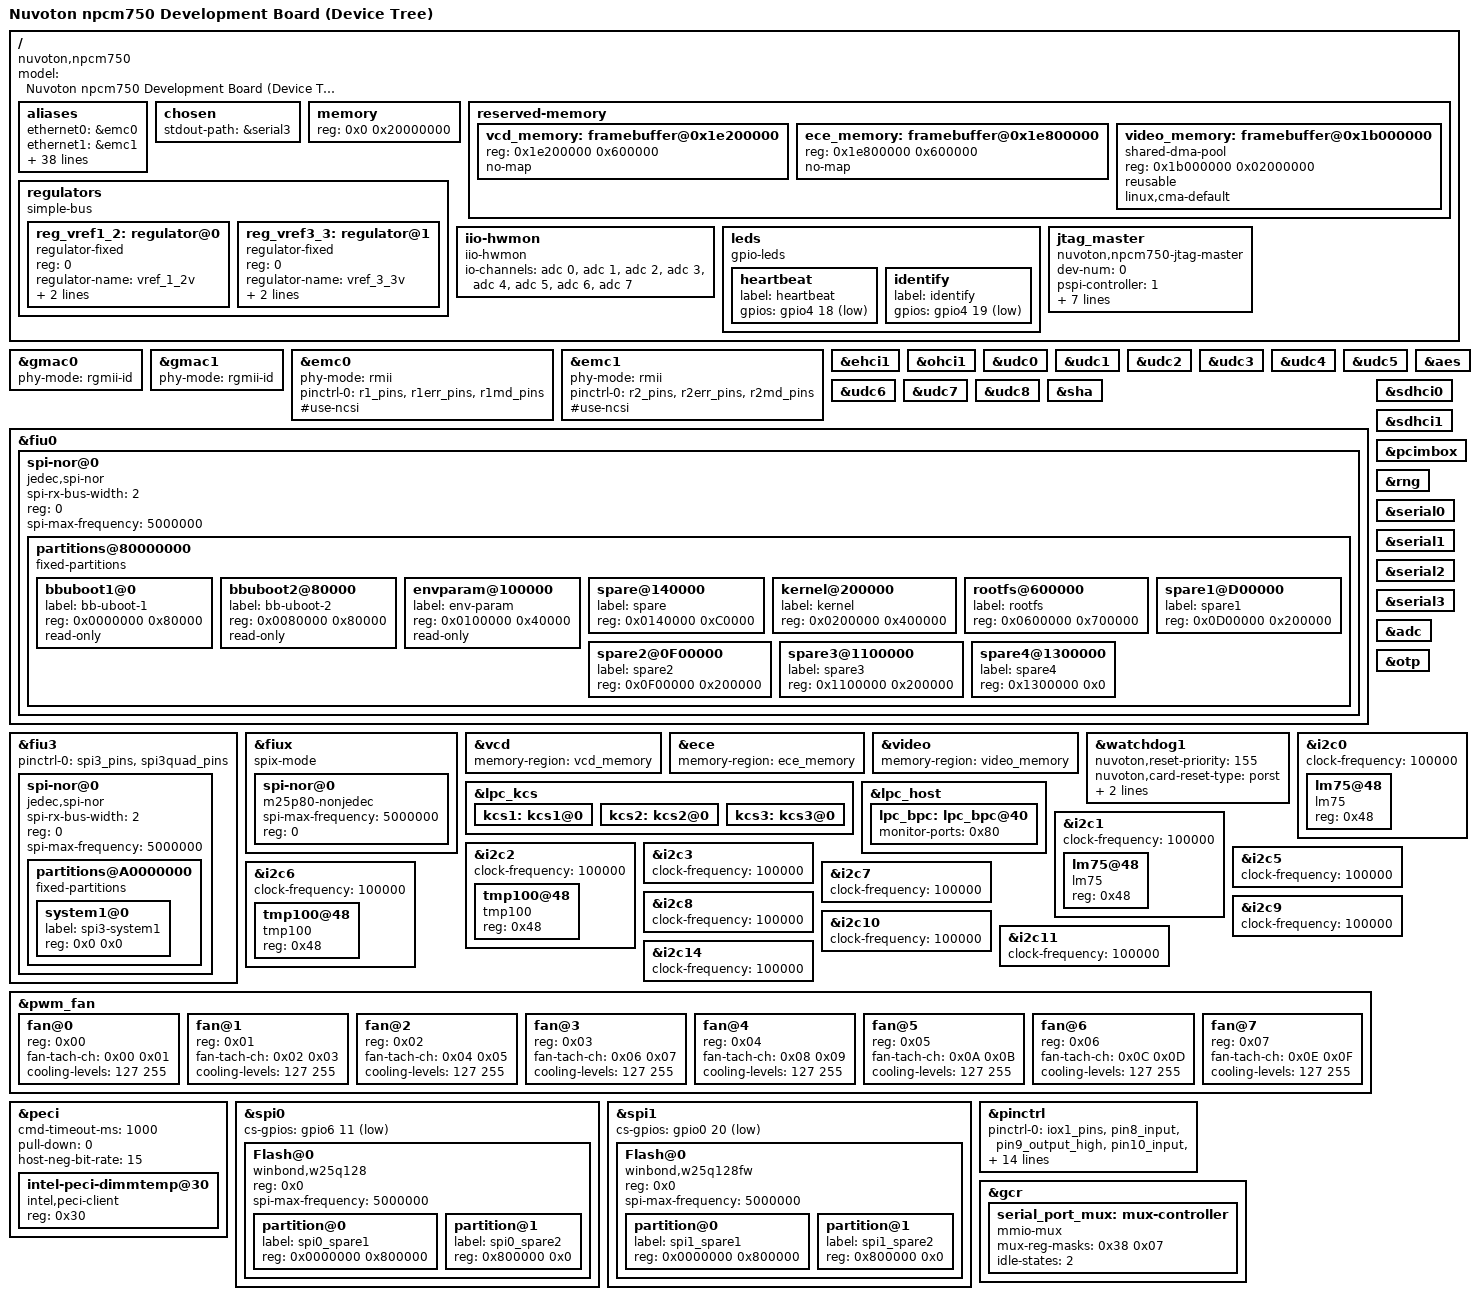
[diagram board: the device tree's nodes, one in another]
// SPDX-License-Identifier: GPL-2.0
// Copyright (c) 2018 Nuvoton Technology tomer.maimon@nuvoton.com
// Copyright 2018 Google, Inc.

/dts-v1/;
#include "nuvoton-npcm750.dtsi"
#include "dt-bindings/gpio/gpio.h"
#include "nuvoton-npcm750-pincfg-evb.dtsi"

/ {
	model = "Nuvoton npcm750 Development Board (Device Tree)";
	compatible = "nuvoton,npcm750";

	aliases {
		ethernet0 = &emc0;
		ethernet1 = &emc1;
		ethernet2 = &gmac0;
		ethernet3 = &gmac1;
		serial0 = &serial0;
		serial1 = &serial1;
		serial2 = &serial2;
		serial3 = &serial3;
		udc0 = &udc0;
		udc1 = &udc1;
		udc2 = &udc2;
		udc3 = &udc3;
		udc4 = &udc4;
		udc5 = &udc5;
		udc6 = &udc6;
		udc7 = &udc7;
		udc8 = &udc8;
		/* udc9 = &udc9; */
		emmc0 = &sdhci0;
		emmc1 = &sdhci1;
		i2c0 = &i2c0;
		i2c1 = &i2c1;
		i2c2 = &i2c2;
		i2c3 = &i2c3;
		i2c4 = &i2c4;
		i2c5 = &i2c5;
		i2c6 = &i2c6;
		i2c7 = &i2c7;
		i2c8 = &i2c8;
		i2c9 = &i2c9;
		i2c10 = &i2c10;
		i2c11 = &i2c11;
		i2c12 = &i2c12;
		i2c13 = &i2c13;
		i2c14 = &i2c14;
		i2c15 = &i2c15;
		spi0 = &spi0;
		spi1 = &spi1;
		fiu0 = &fiu0;
		fiu1 = &fiu3;
		fiu2 = &fiux;
	};

	chosen {
		stdout-path = &serial3;
	};

	memory {
		device_type = "memory";
		reg = <0x0 0x20000000>;
	};

	reserved-memory {
		#address-cells = <1>;
		#size-cells = <1>;
		ranges;

		vcd_memory: framebuffer@0x1e200000 {
			reg = <0x1e200000 0x600000>;
			no-map;
		};

		ece_memory: framebuffer@0x1e800000 {
			reg = <0x1e800000 0x600000>;
			no-map;
		};

		video_memory: framebuffer@0x1b000000 {
			compatible = "shared-dma-pool";
			reg = <0x1b000000 0x02000000>;
			reusable;
			linux,cma-default;
		};
	};

	regulators {
		compatible = "simple-bus";
		#address-cells = <1>;
		#size-cells = <0>;

		reg_vref1_2: regulator@0 {
			compatible = "regulator-fixed";
			reg = <0>;
			regulator-name = "vref_1_2v";
			regulator-min-microvolt = <1200000>;
			regulator-max-microvolt = <1200000>;
		};
		reg_vref3_3: regulator@1 {
			compatible = "regulator-fixed";
			reg = <0>;
			regulator-name = "vref_3_3v";
			regulator-min-microvolt = <3300000>;
			regulator-max-microvolt = <3300000>;
		};
	};

 	iio-hwmon {
		compatible = "iio-hwmon";
		io-channels = <&adc 0>, <&adc 1>, <&adc 2>, <&adc 3>,
			<&adc 4>, <&adc 5>, <&adc 6>, <&adc 7>;
	};

	leds {
		compatible = "gpio-leds";

		heartbeat {
			label = "heartbeat";
			gpios = <&gpio4 18 1>;
		};

		identify {
			label = "identify";
			gpios = <&gpio4 19 1>;
		};
	};

	jtag_master {
		compatible = "nuvoton,npcm750-jtag-master";
		#address-cells = <1>;
		#size-cells = <1>;

		dev-num = <0>;
		pspi-controller = <1>; /* pspi1 */
		reg = <0xf0200000 0x1000>;
		interrupts = <GIC_SPI 31 IRQ_TYPE_LEVEL_HIGH>;
		clocks = <&clk NPCM7XX_CLK_APB5>;

		jtag-gpios = <&gpio5 15 GPIO_ACTIVE_HIGH>, /* TCK */
				<&gpio5 16 GPIO_ACTIVE_HIGH>, /* TDI */
				<&gpio5 17 GPIO_ACTIVE_HIGH>, /* TDO */
				<&gpio6 11 GPIO_ACTIVE_HIGH>; /* TMS */
		jtag-gpios-reg = <0xf0015000 0xf0015000
						  0xf0015000 0xf0016000>;
		status = "okay";
	};
};

&gmac0 {
	phy-mode = "rgmii-id";
	status = "okay";
};

&gmac1 {
	phy-mode = "rgmii-id";
	status = "okay";
};

&emc0 {
	phy-mode = "rmii";
	pinctrl-0 = <&r1_pins
			&r1err_pins
			&r1md_pins>;
	#use-ncsi; /* add this to support ncsi */
	status = "okay";
};

&emc1 {
	phy-mode = "rmii";
	pinctrl-0 = <&r2_pins
			&r2err_pins
			&r2md_pins>;
	#use-ncsi; /* add this to support ncsi */
	status = "okay";
};

&ehci1 {
	status = "okay";
};

&ohci1 {
	status = "okay";
};

&udc0 {
	status = "okay";
};

&udc1 {
	status = "okay";
};

&udc2 {
	status = "okay";
};

&udc3 {
	status = "okay";
};

&udc4 {
	status = "okay";
};

&udc5 {
	status = "okay";
};

&udc6 {
	status = "okay";
};

&udc7 {
	status = "okay";
};

&udc8 {
	status = "okay";
};

/* using USB host instead of UDC9*/ 
/*&udc9 {
	status = "okay";
}; */

&aes {
	status = "okay";
};

&sha {
	status = "okay";
};

&fiu0 {
	status = "okay";
	spi-nor@0 {
		compatible = "jedec,spi-nor";
		#address-cells = <1>;
		#size-cells = <1>;
		spi-rx-bus-width = <2>;
		reg = <0>;
		spi-max-frequency = <5000000>;
		partitions@80000000 {
			compatible = "fixed-partitions";
			#address-cells = <1>;
			#size-cells = <1>;
			bbuboot1@0 {
				label = "bb-uboot-1";
				reg = <0x0000000 0x80000>;
				read-only;
				};
			bbuboot2@80000 {
				label = "bb-uboot-2";
				reg = <0x0080000 0x80000>;
				read-only;
				};
			envparam@100000 {
				label = "env-param";
				reg = <0x0100000 0x40000>;
				read-only;
				};
			spare@140000 {
				label = "spare";
				reg = <0x0140000 0xC0000>;
				};
			kernel@200000 {
				label = "kernel";
				reg = <0x0200000 0x400000>;
				};
			rootfs@600000 {
				label = "rootfs";
				reg = <0x0600000 0x700000>;
				};
			spare1@D00000 {
				label = "spare1";
				reg = <0x0D00000 0x200000>;
				};
			spare2@0F00000 {
				label = "spare2";
				reg = <0x0F00000 0x200000>;
				};
			spare3@1100000 {
				label = "spare3";
				reg = <0x1100000 0x200000>;
				};
			spare4@1300000 {
				label = "spare4";
				reg = <0x1300000 0x0>;
			};
		};
	};
};

&fiu3 {
	pinctrl-0 = <&spi3_pins>, <&spi3quad_pins>;
	status = "okay";
	spi-nor@0 {
		compatible = "jedec,spi-nor";
		#address-cells = <1>;
		#size-cells = <1>;
		spi-rx-bus-width = <2>;
		reg = <0>;
		spi-max-frequency = <5000000>;
		partitions@A0000000 {
			compatible = "fixed-partitions";
			#address-cells = <1>;
			#size-cells = <1>;
			system1@0 {
				label = "spi3-system1";
				reg = <0x0 0x0>;
			};
		};
	};
};

&fiux {
	status = "okay";
	spix-mode;
	spi-nor@0 {
		compatible = "m25p80-nonjedec";
		spi-max-frequency = <5000000>;
		#address-cells = <1>;
		#size-cells = <1>;
		reg = <0>;
	};
};

/* using GPIO29 for reset RC and EP signal */
/*&pci_rc {
	rst-rc-pci = <&gpio0 29 1>;
	rst-ep-pci = <&gpio0 29 1>;
	status = "okay";
};*/

&sdhci0 {
	status = "okay";
};

&sdhci1 {
	status = "okay";
};

&pcimbox {
	status = "okay";
};

&vcd {
	status = "okay";
	memory-region = <&vcd_memory>;
};

&ece {
	status = "okay";
	memory-region = <&ece_memory>;
};

&video {
	memory-region = <&video_memory>;
	status = "okay";
};

&watchdog1 {
	nuvoton,reset-priority = <155>;
	nuvoton,card-reset-type = "porst";
	nuvoton,ext1-reset-type = "wd1";
	nuvoton,ext2-reset-type = "sw2";
	status = "okay";
};

&rng {
	status = "okay";
};

&serial0 {
	status = "okay";
};

&serial1 {
	status = "okay";
};

&serial2 {
	status = "okay";
};

&serial3 {
	status = "okay";
};

&adc {
	/* enable external vref */
	/*vref-supply = <&reg_vref1_2>;*/
	#io-channel-cells = <1>;
	status = "okay";
};

&otp {
	status = "okay";
};

&lpc_kcs {
	kcs1: kcs1@0 {
		status = "okay";
	};

	kcs2: kcs2@0 {
		status = "okay";
	};

	kcs3: kcs3@0 {
		status = "okay";
	};
};

&lpc_host {
	lpc_bpc: lpc_bpc@40 {
		monitor-ports = <0x80>;
		status = "okay";
	};
};

/* I2C mux example */
/*i2cmux0 {
	compatible = "nuvoton,i2c-mux-npcm";
	#address-cells = <1>;
	#size-cells = <0>;

	status = "okay";
	i2c-parent = <&i2c1>;
	syscon = <&gcr>;
	nuvoton,i2c-number = <1>;

	pinctrl-names = "default";
	pinctrl-0 = <&smb1_pins &smb1b_pins &smb1c_pins &smb1d_pins>;
	i2c_segment_number = <0>, <1>, <2>, <3>;

	i2c@2 {
		reg = <2>;
		#address-cells = <1>;
		#size-cells = <0>;
		status = "okay";

		eeprom {
			compatible = "atmel,24c04";
			reg = <0x50>;
			status = "okay";
		};
	};
};*/

/* lm75 on SVB */
&i2c0 {
	clock-frequency = <100000>;
	status = "okay";
	lm75@48 {
		compatible = "lm75";
		reg = <0x48>;
		status = "okay";
	};
};

/* lm75 on EB */
&i2c1 {
	clock-frequency = <100000>;
	status = "okay";
	lm75@48 {
		compatible = "lm75";
		reg = <0x48>;
		status = "okay";
	};
};

/* tmp100 on EB */
&i2c2 {
	clock-frequency = <100000>;
	status = "okay";
	tmp100@48 {
		compatible = "tmp100";
		reg = <0x48>;
		status = "okay";
	};
};

&i2c3 {
	clock-frequency = <100000>;
	status = "okay";
};

&i2c5 {
	clock-frequency = <100000>;
	status = "okay";
};

/* tmp100 on SVB */
&i2c6 {
	clock-frequency = <100000>;
	status = "okay";
	tmp100@48 {
		compatible = "tmp100";
		reg = <0x48>;
		status = "okay";
	};
};

&i2c7 {
	clock-frequency = <100000>;
	status = "okay";
};

&i2c8 {
	clock-frequency = <100000>;
	status = "okay";
};

&i2c9 {
	clock-frequency = <100000>;
	status = "okay";
};

&i2c10 {
	clock-frequency = <100000>;
	status = "okay";
};

&i2c11 {
	clock-frequency = <100000>;
	status = "okay";
};

&i2c14 {
	clock-frequency = <100000>;
	status = "okay";
};

&pwm_fan {
	status = "okay";
	fan@0 {
		reg = <0x00>;
		fan-tach-ch = /bits/ 8 <0x00 0x01>;
		cooling-levels = <127 255>;
	};
	fan@1 {
		reg = <0x01>;
		fan-tach-ch = /bits/ 8 <0x02 0x03>;
		cooling-levels = /bits/ 8 <127 255>;
	};
	fan@2 {
		reg = <0x02>;
		fan-tach-ch = /bits/ 8 <0x04 0x05>;
		cooling-levels = /bits/ 8 <127 255>;
	};
	fan@3 {
		reg = <0x03>;
		fan-tach-ch = /bits/ 8 <0x06 0x07>;
		cooling-levels = /bits/ 8 <127 255>;
	};
	fan@4 {
		reg = <0x04>;
		fan-tach-ch = /bits/ 8 <0x08 0x09>;
		cooling-levels = /bits/ 8 <127 255>;
	};
	fan@5 {
		reg = <0x05>;
		fan-tach-ch = /bits/ 8 <0x0A 0x0B>;
		cooling-levels = /bits/ 8 <127 255>;
	};
	fan@6 {
		reg = <0x06>;
		fan-tach-ch = /bits/ 8 <0x0C 0x0D>;
		cooling-levels = /bits/ 8 <127 255>;
	};
	fan@7 {
		reg = <0x07>;
		fan-tach-ch = /bits/ 8 <0x0E 0x0F>;
		cooling-levels = /bits/ 8 <127 255>;
	};
};

&peci {
	cmd-timeout-ms = <1000>;
	pull-down = <0>;
	host-neg-bit-rate = <15>;
	status = "okay";
	intel-peci-dimmtemp@30 {
		compatible = "intel,peci-client";
		reg = <0x30>;
		status = "okay";
	};
};

&spi0 {
	cs-gpios = <&gpio6 11 GPIO_ACTIVE_LOW>;
	status = "okay";
	Flash@0 {
		compatible = "winbond,w25q128",
		"jedec,spi-nor";
		reg = <0x0>;
		#address-cells = <1>;
		#size-cells = <1>;
		spi-max-frequency = <5000000>;
		partition@0 {
			label = "spi0_spare1";
			reg = <0x0000000 0x800000>;
		};
		partition@1 {
			label = "spi0_spare2";
			reg = <0x800000 0x0>;
		};
	};
};

&spi1 {
	cs-gpios = <&gpio0 20 GPIO_ACTIVE_LOW>;
	status = "okay";
	Flash@0 {
		compatible = "winbond,w25q128fw",
		"jedec,spi-nor";
		reg = <0x0>;
		#address-cells = <1>;
		#size-cells = <1>;
		spi-max-frequency = <5000000>;
		partition@0 {
			label = "spi1_spare1";
			reg = <0x0000000 0x800000>;
		};
		partition@1 {
			label = "spi1_spare2";
			reg = <0x800000 0x0>;
		};
	};
};

&pinctrl {
	pinctrl-names = "default";
	pinctrl-0 = <	&iox1_pins
			&pin8_input
			&pin9_output_high
			&pin10_input
			&pin11_output_high
			&pin16_input
			&pin24_output_high
			&pin25_output_low
			&pin32_output_high
			&jtag2_pins
			&pin61_output_high
			&pin62_output_high
			&pin63_output_high
			&lpc_pins
			&pin160_input
			&pin162_input
			&pin168_input
			&pin169_input
			&pin170_input
			&pin187_output_high
			&pin190_input
			&pin191_output_high
			&pin192_output_high
			&pin197_output_low
			&ddc_pins
			&pin218_input
			&pin219_output_low
			&pin220_output_low
			&pin221_output_high
			&pin222_input
			&pin223_output_low
			&spix_pins
			&pin228_output_low
			&pin231_output_high
			&pin255_input>;
};


&gcr {
	serial_port_mux: mux-controller {
		compatible = "mmio-mux";
		#mux-control-cells = <1>;

		mux-reg-masks = <0x38 0x07>;
		idle-states = <2>; /* Serial port mode 3 (takeover) */
	};
};
